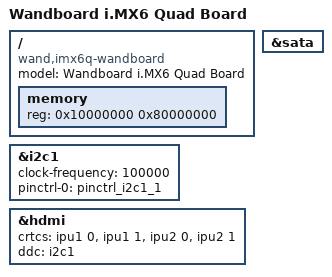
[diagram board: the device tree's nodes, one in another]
/*
 * Copyright 2013 Freescale Semiconductor, Inc.
 *
 * Author: Fabio Estevam <fabio.estevam@freescale.com>
 *
 * This program is free software; you can redistribute it and/or modify
 * it under the terms of the GNU General Public License version 2 as
 * published by the Free Software Foundation.
 *
 */
/dts-v1/;
#include "imx6q.dtsi"
#include "imx6qdl-wandboard.dtsi"

/ {
	model = "Wandboard i.MX6 Quad Board";
	compatible = "wand,imx6q-wandboard", "fsl,imx6q";

	memory {
		reg = <0x10000000 0x80000000>;
	};
};

&sata {
	status = "okay";
};

&i2c1 {
	clock-frequency = <100000>;
	pinctrl-names = "default";
	pinctrl-0 = <&pinctrl_i2c1_1>;
	status = "okay";
};

&hdmi {
	crtcs = <&ipu1 0 &ipu1 1 &ipu2 0 &ipu2 1>;
	ddc = <&i2c1>;
	status = "okay";
};
